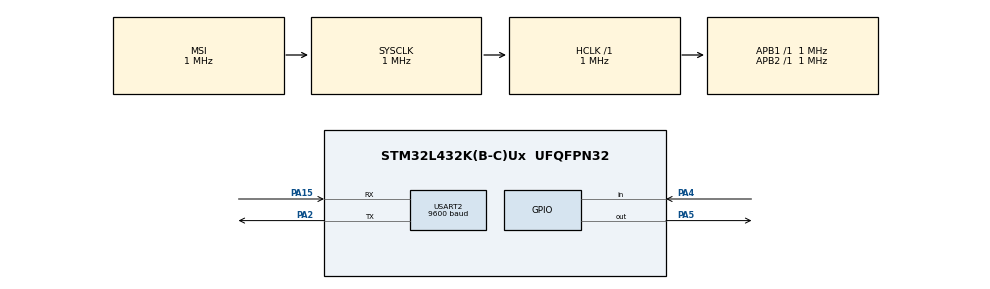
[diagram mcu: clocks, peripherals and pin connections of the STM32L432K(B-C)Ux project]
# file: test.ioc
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Mcu.Family=STM32L4
Mcu.Name=STM32L432K(B-C)Ux
Mcu.Package=UFQFPN32
NVIC.PriorityGroup=NVIC_PRIORITYGROUP_4
PA15\ (JTDI).Mode=Asynchronous
PA15\ (JTDI).Signal=USART2_RX
PA2.Mode=Asynchronous
PA2.Signal=USART2_TX
PA4.Signal=GPIO_Input
PA5.Signal=GPIO_Output
ProjectManager.HeapSize=0x200
ProjectManager.StackSize=0x400
ProjectManager.TargetToolchain=MDK-ARM V5
RCC.ADCFreq_Value=4000000
RCC.AHBFreq_Value=1000000
RCC.APB1Freq_Value=1000000
RCC.APB1TimFreq_Value=1000000
RCC.APB2Freq_Value=1000000
RCC.APB2TimFreq_Value=1000000
RCC.CortexFreq_Value=1000000
RCC.HCLKFreq_Value=1000000
RCC.HSE_VALUE=8000000
RCC.HSI48_VALUE=48000000
RCC.HSI_VALUE=16000000
RCC.LSE_VALUE=32768
RCC.MSIClockRange=RCC_MSIRANGE_4
RCC.MSI_VALUE=1000000
RCC.SYSCLKFreq_VALUE=1000000
RCC.USBFreq_Value=4000000
RCC.VCOOutputFreq_Value=8000000
USART2.BaudRate=9600
USART2.VirtualMode-Asynchronous=VM_ASYNC
board=custom

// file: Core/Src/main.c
/* USER CODE BEGIN Header */
/**
  ******************************************************************************
  * @file           : main.c
  * @brief          : Main program body
  ******************************************************************************
  * @attention
  *
  * <h2><center>&copy; Copyright (c) 2021 STMicroelectronics.
  * All rights reserved.</center></h2>
  *
  * This software component is licensed by ST under BSD 3-Clause license,
  * the "License"; You may not use this file except in compliance with the
  * License. You may obtain a copy of the License at:
  *                        opensource.org/licenses/BSD-3-Clause
  *
  ******************************************************************************
  */
/* USER CODE END Header */
#include "main.h"
#include "hx711.h"
#include "stdio.h"

UART_HandleTypeDef huart2;

void SystemClock_Config(void);
static void MX_GPIO_Init(void);
static void MX_USART2_UART_Init(void);
/* USER CODE BEGIN PFP */
hx711_t loadcell;
int weight;
/* USER CODE END PFP */

int main(void)
{

  /* MCU Configuration--------------------------------------------------------*/

  /* Reset of all peripherals, Initializes the Flash interface and the Systick. */
  HAL_Init();

  /* Configure the system clock */
  SystemClock_Config();

  /* Initialize all configured peripherals */
  MX_GPIO_Init();
  MX_USART2_UART_Init();

  /* Infinite loop */
  /* USER CODE BEGIN WHILE */
	  hx711_init(&loadcell, GPIOA, GPIO_PIN_4, GPIOA, GPIO_PIN_5);
		hx711_tare(&loadcell, 10);
		hx711_coef_set(&loadcell, 146.5); // read afer calibration

	//hx711_calibration(&loadcell, 2366, 0, 1);
	char out[10];
	char newline[2] = "\r\n";
 while (1)
  {
    /* USER CODE END WHILE */
		HAL_Delay(500);

    weight = hx711_weight(&loadcell, 10);
		weight=weight-5815;
		sprintf(out,"%d",weight);
		HAL_UART_Transmit(&huart2,(uint8_t *)out,sizeof(out),HAL_MAX_DELAY);
		HAL_UART_Transmit(&huart2,(uint8_t *)newline,sizeof(newline),HAL_MAX_DELAY);

  }
}

void SystemClock_Config(void)
{
  RCC_OscInitTypeDef RCC_OscInitStruct = {0};
  RCC_ClkInitTypeDef RCC_ClkInitStruct = {0};

  /** Configure the main internal regulator output voltage
  */
  if (HAL_PWREx_ControlVoltageScaling(PWR_REGULATOR_VOLTAGE_SCALE1) != HAL_OK)
  {
    Error_Handler();
  }
  /** Initializes the RCC Oscillators according to the specified parameters
  * in the RCC_OscInitTypeDef structure.
  */
  RCC_OscInitStruct.OscillatorType = RCC_OSCILLATORTYPE_MSI;
  RCC_OscInitStruct.MSIState = RCC_MSI_ON;
  RCC_OscInitStruct.MSICalibrationValue = 0;
  RCC_OscInitStruct.MSIClockRange = RCC_MSIRANGE_4;
  RCC_OscInitStruct.PLL.PLLState = RCC_PLL_NONE;
  if (HAL_RCC_OscConfig(&RCC_OscInitStruct) != HAL_OK)
  {
    Error_Handler();
  }
  /** Initializes the CPU, AHB and APB buses clocks
  */
  RCC_ClkInitStruct.ClockType = RCC_CLOCKTYPE_HCLK|RCC_CLOCKTYPE_SYSCLK
                              |RCC_CLOCKTYPE_PCLK1|RCC_CLOCKTYPE_PCLK2;
  RCC_ClkInitStruct.SYSCLKSource = RCC_SYSCLKSOURCE_MSI;
  RCC_ClkInitStruct.AHBCLKDivider = RCC_SYSCLK_DIV1;
  RCC_ClkInitStruct.APB1CLKDivider = RCC_HCLK_DIV1;
  RCC_ClkInitStruct.APB2CLKDivider = RCC_HCLK_DIV1;

  if (HAL_RCC_ClockConfig(&RCC_ClkInitStruct, FLASH_LATENCY_0) != HAL_OK)
  {
    Error_Handler();
  }
}

static void MX_USART2_UART_Init(void)
{

  huart2.Instance = USART2;
  huart2.Init.BaudRate = 9600;
  huart2.Init.WordLength = UART_WORDLENGTH_8B;
  huart2.Init.StopBits = UART_STOPBITS_1;
  huart2.Init.Parity = UART_PARITY_NONE;
  huart2.Init.Mode = UART_MODE_TX_RX;
  huart2.Init.HwFlowCtl = UART_HWCONTROL_NONE;
  huart2.Init.OverSampling = UART_OVERSAMPLING_16;
  huart2.Init.OneBitSampling = UART_ONE_BIT_SAMPLE_DISABLE;
  huart2.AdvancedInit.AdvFeatureInit = UART_ADVFEATURE_NO_INIT;
  if (HAL_UART_Init(&huart2) != HAL_OK)
  {
    Error_Handler();
  }

}

static void MX_GPIO_Init(void)
{
  GPIO_InitTypeDef GPIO_InitStruct = {0};

  /* GPIO Ports Clock Enable */
  __HAL_RCC_GPIOA_CLK_ENABLE();

  /*Configure GPIO pin Output Level */
  HAL_GPIO_WritePin(GPIOA, GPIO_PIN_5, GPIO_PIN_RESET);

  /*Configure GPIO pin : PA4 */
  GPIO_InitStruct.Pin = GPIO_PIN_4;
  GPIO_InitStruct.Mode = GPIO_MODE_INPUT;
  GPIO_InitStruct.Pull = GPIO_NOPULL;
  HAL_GPIO_Init(GPIOA, &GPIO_InitStruct);

  /*Configure GPIO pin : PA5 */
  GPIO_InitStruct.Pin = GPIO_PIN_5;
  GPIO_InitStruct.Mode = GPIO_MODE_OUTPUT_PP;
  GPIO_InitStruct.Pull = GPIO_NOPULL;
  GPIO_InitStruct.Speed = GPIO_SPEED_FREQ_LOW;
  HAL_GPIO_Init(GPIOA, &GPIO_InitStruct);

}

void Error_Handler(void)
{
  __disable_irq();
  while (1)
  {
  }
}

/************************ (C) COPYRIGHT STMicroelectronics *****END OF FILE****/
